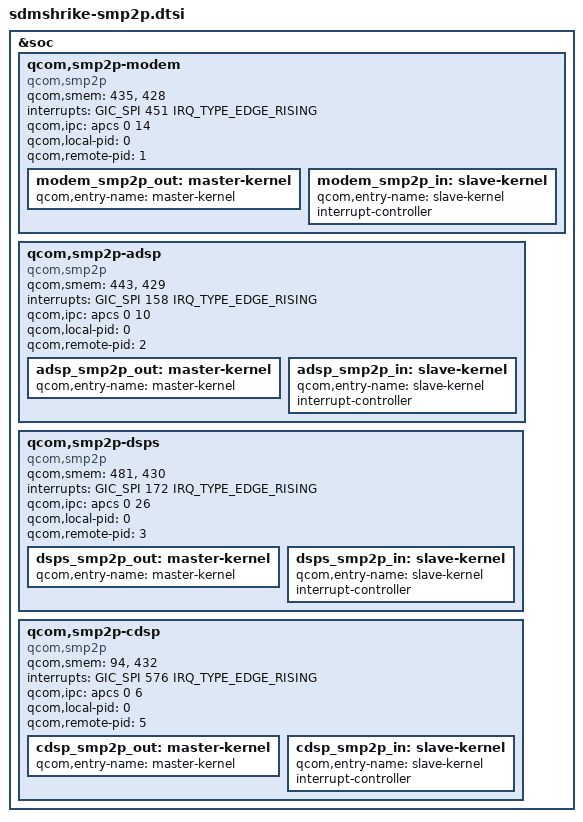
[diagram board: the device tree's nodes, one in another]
/* Copyright (c) 2018, The Linux Foundation. All rights reserved.
 *
 * This program is free software; you can redistribute it and/or modify
 * it under the terms of the GNU General Public License version 2 and
 * only version 2 as published by the Free Software Foundation.
 *
 * This program is distributed in the hope that it will be useful,
 * but WITHOUT ANY WARRANTY; without even the implied warranty of
 * MERCHANTABILITY or FITNESS FOR A PARTICULAR PURPOSE.  See the
 * GNU General Public License for more details.
 */

#include <dt-bindings/interrupt-controller/arm-gic.h>

&soc {

	qcom,smp2p-modem {
		compatible = "qcom,smp2p";
		qcom,smem = <435>, <428>;
		interrupts = <GIC_SPI 451 IRQ_TYPE_EDGE_RISING>;
		qcom,ipc = <&apcs 0 14>;
		qcom,local-pid = <0>;
		qcom,remote-pid = <1>;

		modem_smp2p_out: master-kernel {
			qcom,entry-name = "master-kernel";
			#qcom,smem-state-cells = <1>;
		};

		modem_smp2p_in: slave-kernel {
			qcom,entry-name = "slave-kernel";
			interrupt-controller;
			#interrupt-cells = <2>;
		};
	};

	qcom,smp2p-adsp {
		compatible = "qcom,smp2p";
		qcom,smem = <443>, <429>;
		interrupts = <GIC_SPI 158 IRQ_TYPE_EDGE_RISING>;
		qcom,ipc = <&apcs 0 10>;
		qcom,local-pid = <0>;
		qcom,remote-pid = <2>;

		adsp_smp2p_out: master-kernel {
			qcom,entry-name = "master-kernel";
			#qcom,smem-state-cells = <1>;
		};

		adsp_smp2p_in: slave-kernel {
			qcom,entry-name = "slave-kernel";
			interrupt-controller;
			#interrupt-cells = <2>;
		};
	};

	qcom,smp2p-dsps {
		compatible = "qcom,smp2p";
		qcom,smem = <481>, <430>;
		interrupts = <GIC_SPI 172 IRQ_TYPE_EDGE_RISING>;
		qcom,ipc = <&apcs 0 26>;
		qcom,local-pid = <0>;
		qcom,remote-pid = <3>;

		dsps_smp2p_out: master-kernel {
			qcom,entry-name = "master-kernel";
			#qcom,smem-state-cells = <1>;
		};

		dsps_smp2p_in: slave-kernel {
			qcom,entry-name = "slave-kernel";
			interrupt-controller;
			#interrupt-cells = <2>;
		};
	};

	qcom,smp2p-cdsp {
		compatible = "qcom,smp2p";
		qcom,smem = <94>, <432>;
		interrupts = <GIC_SPI 576 IRQ_TYPE_EDGE_RISING>;
		qcom,ipc = <&apcs 0 6>;
		qcom,local-pid = <0>;
		qcom,remote-pid = <5>;

		cdsp_smp2p_out: master-kernel {
			qcom,entry-name = "master-kernel";
			#qcom,smem-state-cells = <1>;
		};

		cdsp_smp2p_in: slave-kernel {
			qcom,entry-name = "slave-kernel";
			interrupt-controller;
			#interrupt-cells = <2>;
		};
	};
};
